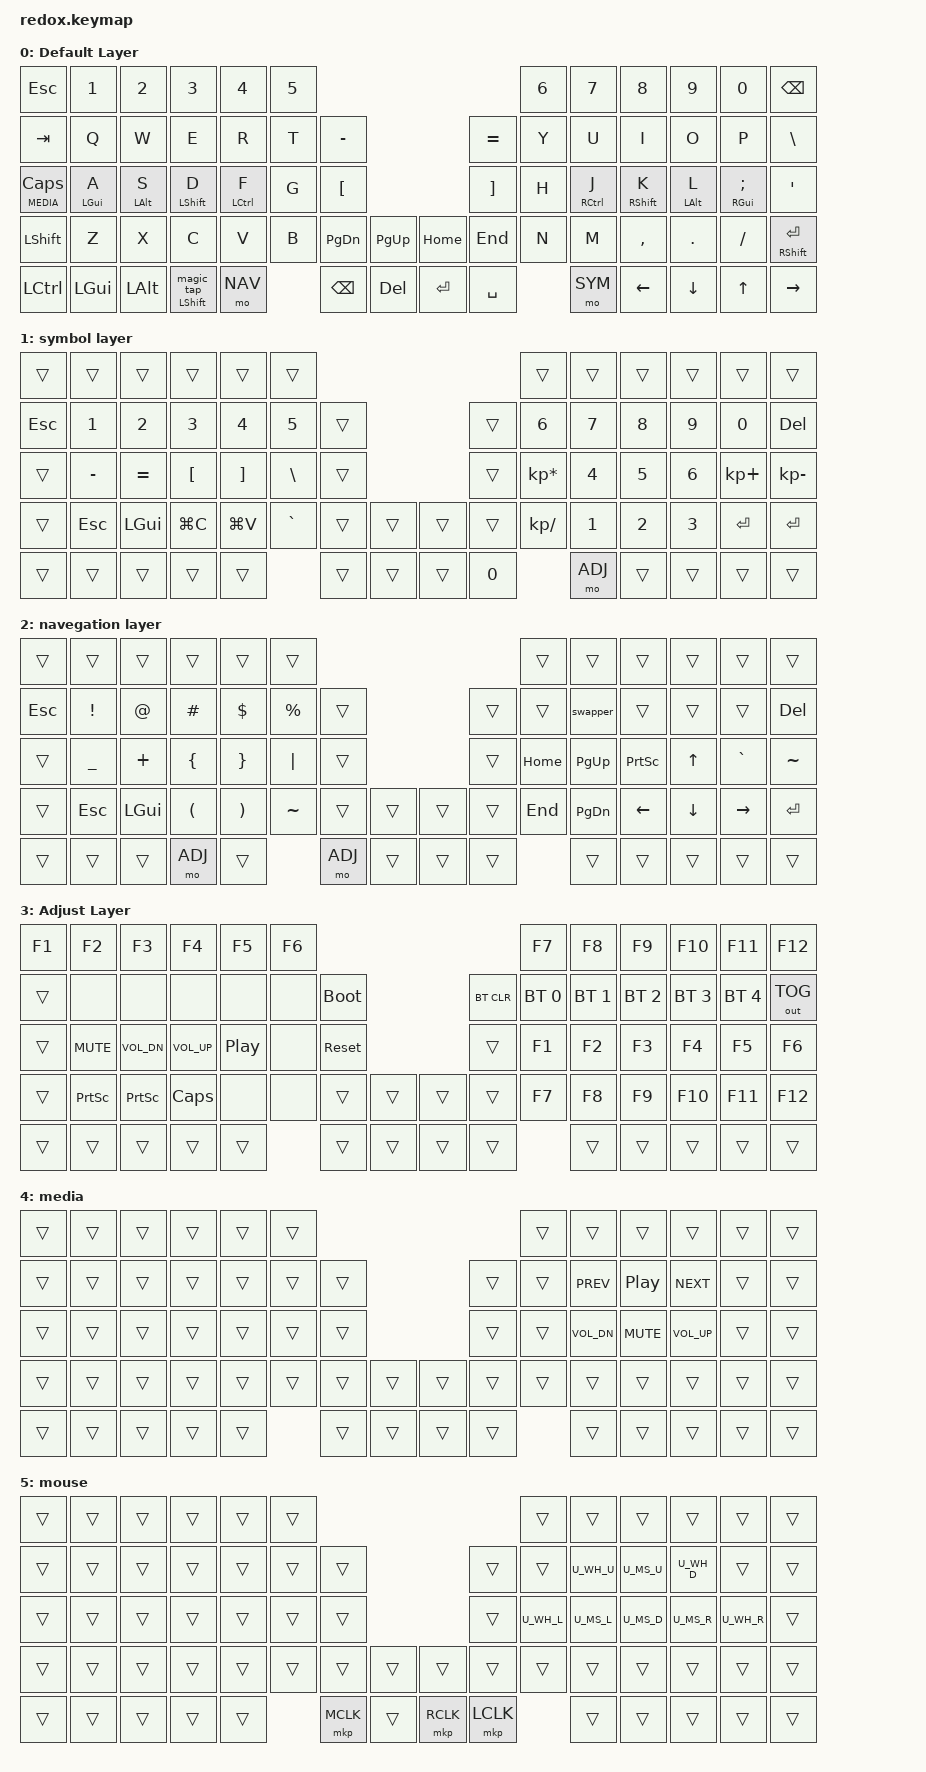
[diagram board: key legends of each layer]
/*
 * Copyright (c) 2021 The ZMK Contributors
 *
 * SPDX-License-Identifier: MIT
 */

#include <behaviors.dtsi>
#include <dt-bindings/zmk/bt.h>
#include <dt-bindings/zmk/keys.h>
#include <dt-bindings/zmk/outputs.h>

#include "mouse.dtsi"

// Posiciones por mitad para los hold-trigger de los HRM (layout Redox, 70 teclas)
#define KEYS_L 0 1 2 3 4 5 12 13 14 15 16 17 18 26 27 28 29 30 31 32 40 41 42 43 44 45 46 47
#define KEYS_R 6 7 8 9 10 11 19 20 21 22 23 24 25 33 34 35 36 37 38 39 48 49 50 51 52 53 54 55
#define THUMBS 59 60 61 62 63 64 65

// Capas (las nuevas SIEMPRE al final para no renumerar)
#define DEF   0
#define SYM   1
#define NAV   2
#define ADJ   3
#define MEDIA 4
#define MOUSE 5

// El único &lt del keymap (CAPS/media): balanced para no disparar la capa en rolls
&lt {
    flavor = "balanced";
    tapping-term-ms = <200>;
    quick-tap-ms = <175>;
};

/ {
    behaviors {
        // Home-row mods "timeless" (urob): balanced + prior-idle + positional
        // hold-tap para que no disparen mods tipeando rápido.
        hml: home_row_mod_left {
            compatible = "zmk,behavior-hold-tap";
            #binding-cells = <2>;
            flavor = "balanced";
            tapping-term-ms = <280>;
            quick-tap-ms = <175>;
            require-prior-idle-ms = <150>;
            bindings = <&kp>, <&kp>;
            hold-trigger-key-positions = <KEYS_R THUMBS>;
            hold-trigger-on-release;
        };

        hmr: home_row_mod_right {
            compatible = "zmk,behavior-hold-tap";
            #binding-cells = <2>;
            flavor = "balanced";
            tapping-term-ms = <280>;
            quick-tap-ms = <175>;
            require-prior-idle-ms = <150>;
            bindings = <&kp>, <&kp>;
            hold-trigger-key-positions = <KEYS_L THUMBS>;
            hold-trigger-on-release;
        };

        // Magic thumb (patrón urob): hold = Shift; tap tras alfa = key-repeat;
        // tap en otro contexto = sticky-shift; doble tap = caps_word.
        magic: magic_shift {
            compatible = "zmk,behavior-hold-tap";
            #binding-cells = <2>;
            flavor = "balanced";
            tapping-term-ms = <200>;
            quick-tap-ms = <175>;
            bindings = <&kp>, <&magic_tap>;
        };

        magic_tap: magic_shift_tap {
            compatible = "zmk,behavior-mod-morph";
            #binding-cells = <0>;
            bindings = <&shift_repeat>, <&caps_word>;
            mods = <(MOD_LSFT|MOD_RSFT)>;
        };

        shift_repeat: shift_repeat {
            compatible = "zmk,behavior-adaptive-key";
            #binding-cells = <0>;
            bindings = <&sk LSHFT>;
            repeat {
                trigger-keys = <A B C D E F G H I J K L M N O P Q R S T U V W X Y Z>;
                bindings = <&key_repeat>;
                max-prior-idle-ms = <1200>;
                strict-modifiers;
            };
        };

        // Alt-Tab de una tecla: mantiene Alt hasta que se toca algo no ignorado.
        // Ignorados: shifts (Shift+Tab hacia atrás) y flechas (navegar la grilla).
        swapper: swapper {
            compatible = "zmk,behavior-tri-state";
            #binding-cells = <0>;
            bindings = <&kt LALT>, <&kp TAB>, <&kt LALT>;
            ignored-key-positions = <40 55 66 67 68 69>;
        };

        // Smart-mouse (patrón urob): combo W+P togglea la capa MOUSE; cualquier
        // tecla fuera del cluster de mouse la apaga sola.
        smart_mouse: smart_mouse {
            compatible = "zmk,behavior-tri-state";
            #binding-cells = <0>;
            bindings = <&tog MOUSE>, <&none>, <&tog MOUSE>;
            ignored-key-positions = <21 22 23 34 35 36 37 38 61 63 64>;
            ignored-layers = <MOUSE>;
        };
    };

    combos {
        compatible = "zmk,combos";

        // Clipboard sobre la fila ZXCV: cada combo = letra del atajo + su
        // vecina derecha. prior-idle evita disparos tipeando rápido.
        undo {
            bindings = <&kp LC(Z)>;
            key-positions = <41 42>;
            require-prior-idle-ms = <150>;
        };

        cut {
            bindings = <&kp LC(X)>;
            key-positions = <42 43>;
            require-prior-idle-ms = <150>;
        };

        copy {
            bindings = <&kp LC(C)>;
            key-positions = <43 44>;
            require-prior-idle-ms = <150>;
        };

        paste {
            bindings = <&kp LC(V)>;
            key-positions = <44 45>;
            require-prior-idle-ms = <150>;
        };

        bootloader_izq {
            bindings = <&bootloader>;
            key-positions = <0 62>;
        };

        bootloader_der {
            bindings = <&bootloader>;
            key-positions = <63 11>;
        };

        // Q+W = Esc sin estirar el meñique a la esquina
        esc {
            bindings = <&kp ESC>;
            key-positions = <13 14>;
            require-prior-idle-ms = <150>;
        };

        // Shift izq + Shift/Enter der = Caps Word (mayúsculas hasta espacio)
        caps_word {
            bindings = <&caps_word>;
            key-positions = <40 55>;
        };

        // W+P = capa mouse smart (cross-hand, no necesita prior-idle)
        smart_mouse_combo {
            bindings = <&smart_mouse>;
            key-positions = <14 24>;
            layers = <DEF>;
        };
    };

    keymap {
        compatible = "zmk,keymap";

        default {
            display-name = "Default Layer";

            // --------------------------------------------------------------------------------------------------------------------------------
            // | ESC   |  1  |  2  |   3   |  4  |  5  |                   ---                |  6    |  7    |  8    |  9   | 0  |    BSPC   |
            // | TAB   |  Q  |  W  |   E   |  R  |  T  |   (   |           ---        |  )    |  Y    |  U    |  I    |  O   | P  |     -     |
            // | CAPS  | A/❖ | S/⎇ |  D/⇧  | F/⌃ |  G  |   [   |           ---        |  ]    |  H    | J/⌃   | K/⇧   | L/⎇  | ;/❖|     '     |
            // | SHIFT |  Z  |  X  |   C   |  V  |  B  | PG_UP | PG_DOWN | --- | HOME | END   |  N    |  M    |  ,    |  .   | /  | SHFT(RET) |
            // | UNLK  | ALT | GUI | LOWER |    GUI    | USBOUT| SPACE   | --- | DEL  | SPACE |     RAISE     | LEFT  | DOWN | UP |   RIGHT   |

            bindings = <
&kp ESC           &kp N1        &kp N2        &kp N3  &kp N4  &kp N5                                                      &kp N6  &kp N7  &kp N8     &kp N9    &kp N0    &kp BSPC
&kp TAB           &kp Q         &kp W         &kp E   &kp R   &kp T   &kp MINUS                                &kp EQUAL  &kp Y   &kp U   &kp I      &kp O     &kp P     &kp BSLH
&lt MEDIA CLCK    &hml LGUI A   &hml LALT S   &hml LSHFT D  &hml LCTRL F  &kp G   &kp LBKT                          &kp RBKT   &kp H   &hmr RCTRL J  &hmr RSHFT K  &hmr LALT L  &hmr RGUI SEMI  &kp SQT
&kp LSHFT         &kp Z         &kp X         &kp C         &kp V         &kp B   &kp PAGE_DOWN  &kp PAGE_UP    &kp HOME   &kp END    &kp N   &kp M         &kp COMMA     &kp DOT      &kp FSLH        &mt RSHFT RET
&kp LEFT_CONTROL  &kp LEFT_GUI  &kp LEFT_ALT  &magic LSHFT 0  &mo NAV   &kp BSPC     &kp DEL        &kp ENTER  &kp SPACE          &mo SYM &kp LEFT   &kp DOWN  &kp UP    &kp RIGHT
            >;
        };

        symbol {
            display-name = "symbol layer";

            // --------------------------------------------------------------------------------------------------------------------------
            // | ESC   |  1  |  2  |   3   |   4   |  5  |                   ---              |  6  |  7  |   8  |  9   |  0  |  DEL  |
            // | ESC   |  1  |  2  |   3   |   4   |  5  |   (   |           ---        |  )  |  6  |  7  |   8  |  9   |  0  |  DEL  |
            // | CTRL  |  -  |  =  |   [   |   ]   |  \  |   [   |           ---        |  ]  |  *  |  4  |   5  |  6   |  +  |   -   |
            // | SHIFT | ESC | GUI | COPY  | PASTE |     | PG_UP | PG_DOWN | --- | HOME | END |  \  |  1  |   2  |  3   | RET |  RET  |
            // | CRTL  | ALT | GUI | LOWER |     GUI     | LOWER | SPACE   | --- | DEL  |  0  |    RAISE  | LEFT | DOWN | UP  | RIGHT |

            bindings = <
&trans   &trans     &trans     &trans     &trans     &trans                                       &trans           &trans  &trans  &trans  &trans       &trans
&kp ESC  &kp N1     &kp N2     &kp N3     &kp N4     &kp N5     &trans                    &trans  &kp N6           &kp N7  &kp N8  &kp N9  &kp N0       &kp DEL
&trans   &kp MINUS  &kp EQUAL  &kp LBKT   &kp RBKT   &kp BSLH   &trans                    &trans  &kp KP_MULTIPLY  &kp N4  &kp N5  &kp N6  &kp KP_PLUS  &kp KP_MINUS
&trans   &kp ESC    &kp LGUI   &kp LG(C)  &kp LG(V)  &kp GRAVE  &trans  &trans    &trans  &trans  &kp KP_DIVIDE    &kp N1  &kp N2  &kp N3  &kp RET      &kp RET
&trans   &trans     &trans     &trans     &trans                &trans  &trans    &trans  &kp N0                   &mo ADJ &trans  &trans  &trans       &trans
            >;
        };

        nav {
            display-name = "navegation layer";

            // ----------------------------------------------------------------------------------------------------------------------------
            // | ESC   |  1  |  2  |   3   |  4  |  5  |                   ---                |  6   |  7   |  8   |  9   |  0    |  DEL  |
            // | ESC   |  !  |  @  |   #   |  $  |  %  |   (   |           ---        |  )    |  ^   |  &   |  *   |  (   |  )    |  DEL  |
            // | CTRL  |  _  |  +  |   {   |  }  | "|" |   [   |           ---        |  ]    | HOME | PGUP | PRSC | UP   |  `    |   ~   |
            // | SHIFT | ESC | GUI |   (   |  )  |     | PG_UP | PG_DOWN | --- | HOME | END   | END  | PGDN | LEFT | DOWN | RIGHT |  RET  |
            // | CRTL  | ALT | GUI | LOWER |    GUI    | LOWER | SPACE   | --- | DEL  | SPACE |    RAISE    | LEFT | DOWN | UP    | RIGHT |

            bindings = <
&trans   &trans     &trans    &trans    &trans    &trans                                       &trans    &trans     &trans     &trans    &trans     &trans
&kp ESC  &kp EXCL   &kp AT    &kp HASH  &kp DLLR  &kp PRCNT  &trans                    &trans  &trans    &swapper   &trans     &trans    &trans     &kp DEL
&trans   &kp UNDER  &kp PLUS  &kp LBRC  &kp RBRC  &kp PIPE   &trans                    &trans  &kp HOME  &kp PG_UP  &kp PSCRN  &kp UP    &kp GRAVE  &kp TILDE
&trans   &kp ESC    &kp LGUI  &kp LPAR  &kp RPAR  &kp TILDE  &trans  &trans    &trans  &trans  &kp END   &kp PG_DN  &kp LEFT   &kp DOWN  &kp RIGHT  &kp RET
&trans   &trans     &trans    &mo ADJ   &trans               &mo ADJ &trans    &trans  &trans            &trans     &trans     &trans    &trans     &trans
            >;
        };

        adjust {
            display-name = "Adjust Layer";

            // -----------------------------------------------------------------------------------------
            // |  F1   |  F2   |    F3    |    F4     |     F5     | F6 |                   ---                | F7  | F8  |  F9  |  F10 | F11 | F12        |
            // | TAB   |       |          |           |            |    | BOOTL |           ---        |  )    | BT1 | BT2 |  BT3 |  BT4 | BT5 | OUTPUT TGL |
            // | CTRL  | MUTE  |  Vol Dn  |  Vol Up   | Play/Pause |    | RESET |           ---        |  ]    | F1  | F2  |  F3  |  F4  | F5  | F6         |
            // | SHIFT | PSCRN |  PSCRN   |   CAPS    |            |    | PG_UP | PG_DOWN | --- | HOME | END   | F7  | F8  |  F9  |  F10 | F11 | F12        |
            // | CRTL  | ALT   |  GUI     |   LOWER   |      GUI        | LOWER | SPACE   | --- | DEL  | SPACE |   RAISE   | LEFT | DOWN | UP  |   RIGHT    |

            bindings = <
&kp F1  &kp F2      &kp F3        &kp F4        &kp F5            &kp F6                                             &kp F7        &kp F8        &kp F9        &kp F10       &kp F11       &kp F12
&trans  &none       &none         &none         &none             &none   &bootloader                    &bt BT_CLR  &bt BT_SEL 0  &bt BT_SEL 1  &bt BT_SEL 2  &bt BT_SEL 3  &bt BT_SEL 4  &out OUT_TOG
&trans  &kp K_MUTE  &kp C_VOL_DN  &kp C_VOL_UP  &kp C_PLAY_PAUSE  &none   &sys_reset                     &trans      &kp F1        &kp F2        &kp F3        &kp F4        &kp F5        &kp F6
&trans  &kp PSCRN   &kp PSCRN     &kp CLCK      &none             &none   &trans       &trans    &trans  &trans      &kp F7        &kp F8        &kp F9        &kp F10       &kp F11       &kp F12
&trans  &trans      &trans        &trans        &trans                    &trans       &trans    &trans  &trans                    &trans        &trans        &trans        &trans        &trans
            >;
        };

        media {
            display-name = "media";

            // Hold CAPS (mano izq) + mano derecha:
            // | Prev  | Play  | Next  | en U/I/O
            // | Vol-  | Mute  | Vol+  | en J/K/L

            bindings = <
&trans  &trans  &trans  &trans  &trans  &trans                                      &trans  &trans      &trans            &trans        &trans  &trans
&trans  &trans  &trans  &trans  &trans  &trans  &trans                      &trans  &trans  &kp C_PREV  &kp C_PLAY_PAUSE  &kp C_NEXT    &trans  &trans
&trans  &trans  &trans  &trans  &trans  &trans  &trans                      &trans  &trans  &kp C_VOL_DN &kp K_MUTE       &kp C_VOL_UP  &trans  &trans
&trans  &trans  &trans  &trans  &trans  &trans  &trans  &trans      &trans  &trans  &trans  &trans      &trans            &trans        &trans  &trans
&trans  &trans  &trans  &trans  &trans          &trans  &trans      &trans  &trans          &trans      &trans            &trans        &trans  &trans
            >;
        };

        mouse {
            display-name = "mouse";

            // Activada por combo W+P (smart: se apaga sola al tipear).
            // Puntero en IJKL, scroll U/O (vert) y H/; (horiz),
            // clicks: SPACE der = izq, ENTER der = der, BSPC izq = medio.

            bindings = <
&trans  &trans  &trans  &trans  &trans  &trans                                      &trans   &trans   &trans  &trans   &trans   &trans
&trans  &trans  &trans  &trans  &trans  &trans  &trans                      &trans  &trans   U_WH_U   U_MS_U  U_WH_D   &trans   &trans
&trans  &trans  &trans  &trans  &trans  &trans  &trans                      &trans  U_WH_L   U_MS_L   U_MS_D  U_MS_R   U_WH_R   &trans
&trans  &trans  &trans  &trans  &trans  &trans  &trans  &trans      &trans  &trans  &trans   &trans   &trans  &trans   &trans   &trans
&trans  &trans  &trans  &trans  &trans          &mkp MCLK &trans    &mkp RCLK &mkp LCLK     &trans   &trans   &trans  &trans   &trans
            >;
        };
    };
};
